VERSION ""

NS_ :

BS_:

BU_: Body_Node EngineNode

BO_ 513 Body_Blink: 2 Body_Node
 SG_ Body_Blinker : 0|2@1+ (1,0) [0|3] "-" Vector__XXX

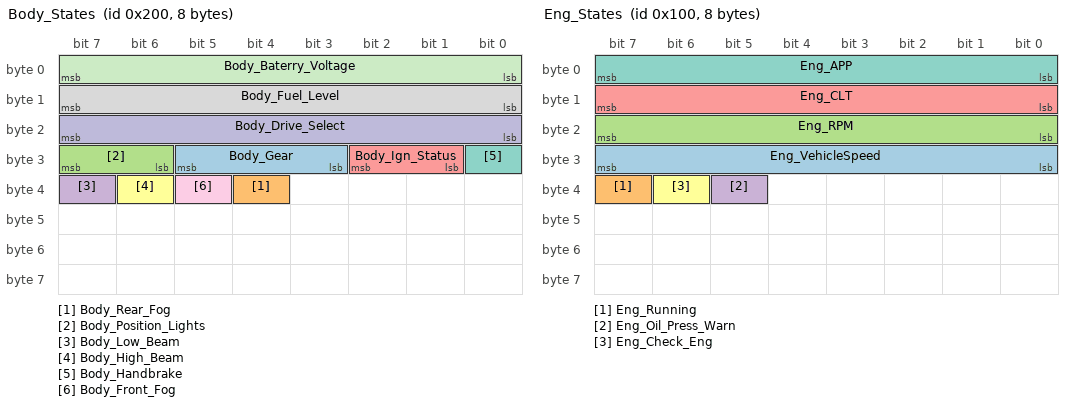
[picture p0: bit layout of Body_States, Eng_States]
BO_ 512 Body_States: 8 Body_Node
 SG_ Body_Gear : 27|3@1+ (1,0) [0|7] "" Vector__XXX
 SG_ Body_Rear_Fog : 36|1@1+ (1,0) [0|1] "-" Vector__XXX
 SG_ Body_Position_Lights : 30|2@1+ (1,0) [0|1] "-" Vector__XXX
 SG_ Body_Low_Beam : 39|1@1+ (1,0) [0|1] "-" Vector__XXX
 SG_ Body_Ign_Status : 25|2@1+ (1,0) [0|3] "-" Vector__XXX
 SG_ Body_High_Beam : 38|1@1+ (1,0) [0|1] "-" Vector__XXX
 SG_ Body_Handbrake : 24|1@1+ (1,0) [0|1] "-" Vector__XXX
 SG_ Body_Fuel_Level : 8|8@1+ (1,0) [0|255] "l" Vector__XXX
 SG_ Body_Front_Fog : 37|1@1+ (1,0) [0|1] "-" Vector__XXX
 SG_ Body_Drive_Select : 16|8@1+ (1,0) [0|255] "-" Vector__XXX
 SG_ Body_Baterry_Voltage : 0|8@1+ (6,0) [0|1530] "mV" Vector__XXX

BO_ 256 Eng_States: 8 EngineNode
 SG_ Eng_VehicleSpeed : 24|8@1+ (1,0) [0|255] "" Vector__XXX
 SG_ Eng_Running : 39|1@1+ (1,0) [0|1] "-" Vector__XXX
 SG_ Eng_RPM : 16|8@1+ (30,0) [0|7650] "RPM" Vector__XXX
 SG_ Eng_Oil_Press_Warn : 37|1@1+ (1,0) [0|1] "mbar" Vector__XXX
 SG_ Eng_CLT : 8|8@1+ (1,-80) [-80|175] "*C" Vector__XXX
 SG_ Eng_Check_Eng : 38|1@1+ (1,0) [0|1] "-" Vector__XXX
 SG_ Eng_APP : 0|8@1+ (0.4,0) [0|102] "%" Vector__XXX

BA_DEF_  "BusType" STRING ;
BA_DEF_DEF_  "BusType" "CAN";
